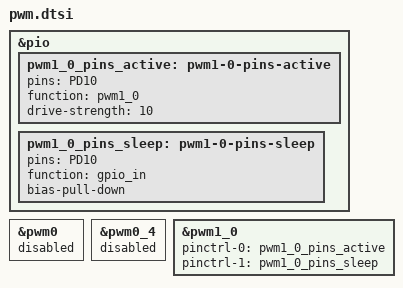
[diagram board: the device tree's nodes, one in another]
/*
 * Cubie A7Z device DTS extension: sysfs PWM for popcorn.
 * Concatenated onto device-a733 cubie_a7z board.dts at pre_build.
 * pwmchip0 channel 0 = PD10 = 40-pin pin 24. UART2/UART3/I2S0 unused.
 */

&pio {
	pwm1_0_pins_active: pwm1-0-pins-active {
		pins = "PD10";
		function = "pwm1_0";
		drive-strength = <10>;
	};

	pwm1_0_pins_sleep: pwm1-0-pins-sleep {
		pins = "PD10";
		function = "gpio_in";
		bias-pull-down;
	};
};

/*
 * pwm0 would otherwise be pwmchip0. Its channel 0 is PB4 (I2S0 MCLK, pin 36)
 * and vendor pwm0_4 is PD22, which is also PCIe reset. Disable the whole
 * controller so pwm1 probes first as /sys/class/pwm/pwmchip0.
 */
&pwm0 {
	status = "disabled";
};

&pwm0_4 {
	status = "disabled";
};

&pwm1_0 {
	pinctrl-names = "active", "sleep";
	pinctrl-0 = <&pwm1_0_pins_active>;
	pinctrl-1 = <&pwm1_0_pins_sleep>;
	status = "okay";
};
